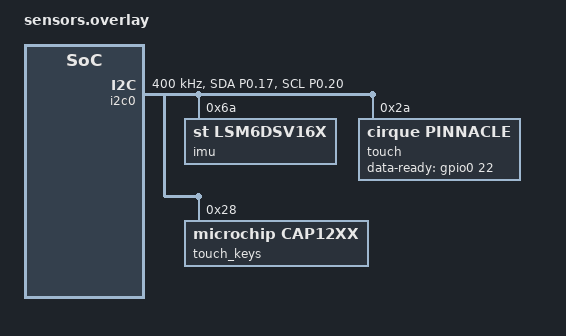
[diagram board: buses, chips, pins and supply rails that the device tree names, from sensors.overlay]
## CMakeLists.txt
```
# Copyright (c) 2026 the OpenSC2-Controller authors
# SPDX-License-Identifier: MIT
cmake_minimum_required(VERSION 3.20.0)

# The OpenSC2 library is a Zephyr module: the OpenSC2-Controller repository. Inside the repository
# it is found here. In a copy of this folder elsewhere, set ZEPHYR_EXTRA_MODULES to your
# OpenSC2-Controller folder (environment variable, or -DZEPHYR_EXTRA_MODULES=<folder>), or list the
# repository in your west manifest (docs/integration.md).
if(EXISTS ${CMAKE_CURRENT_LIST_DIR}/../zephyr/module.yml AND
   EXISTS ${CMAKE_CURRENT_LIST_DIR}/../include/opensc2/opensc2.h)
  list(APPEND ZEPHYR_EXTRA_MODULES ${CMAKE_CURRENT_LIST_DIR}/..)
endif()

# A build variant: a Kconfig fragment of this folder given as EXTRA_CONF_FILE brings the devicetree
# overlay of the same name with it, when there is one (sensors.conf and sensors.overlay). Under
# sysbuild the fragment's name is in the sysbuild cache, not yet a variable here.
set(variant_confs ${EXTRA_CONF_FILE})
if(NOT variant_confs AND DEFINED SYSBUILD_CACHE AND EXISTS "${SYSBUILD_CACHE}")
  file(STRINGS "${SYSBUILD_CACHE}" variant_line REGEX "^EXTRA_CONF_FILE:[A-Z]+=")
  string(REGEX REPLACE "^EXTRA_CONF_FILE:[A-Z]+=" "" variant_confs "${variant_line}")
endif()
# A fragment can build on others of this folder: a line "# OPENSC2_FRAGMENTS: a.conf b.conf" in it
# adds them, with their overlays, before it (all.conf). Zephyr merges this list with the one given.
set(variant_names)
set(variant_parts)
foreach(conf ${variant_confs})
  get_filename_component(variant ${conf} NAME_WE)
  if(EXISTS ${CMAKE_CURRENT_LIST_DIR}/${variant}.conf)
    file(STRINGS ${CMAKE_CURRENT_LIST_DIR}/${variant}.conf parts_line REGEX "^# OPENSC2_FRAGMENTS:")
    string(REGEX REPLACE "^# OPENSC2_FRAGMENTS:" "" parts "${parts_line}")
    separate_arguments(parts)
    foreach(part ${parts})
      list(APPEND variant_parts ${CMAKE_CURRENT_LIST_DIR}/${part})
      get_filename_component(part_name ${part} NAME_WE)
      list(APPEND variant_names ${part_name})
    endforeach()
  endif()
  list(APPEND variant_names ${variant})
endforeach()
if(variant_parts)
  set(EXTRA_CONF_FILE ${variant_parts} ${EXTRA_CONF_FILE})
endif()
foreach(variant ${variant_names})
  if(EXISTS ${CMAKE_CURRENT_LIST_DIR}/${variant}.overlay)
    list(APPEND EXTRA_DTC_OVERLAY_FILE ${CMAKE_CURRENT_LIST_DIR}/${variant}.overlay)
  endif()
endforeach()

find_package(Zephyr REQUIRED HINTS $ENV{ZEPHYR_BASE})
project(opensc2_app LANGUAGES C)

target_sources(app PRIVATE
	src/main.c
	src/inputs.c
	src/status.c
	src/rumble.c
	src/trackpad.c
	src/imu.c
	src/imu_fifo.c
	src/imu_board.c
	src/battery.c
	src/i2c_recover.c
)
```

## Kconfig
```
# Copyright (c) 2026 the OpenSC2-Controller authors
# SPDX-License-Identifier: MIT

menu "OpenSC2 blank canvas"

config APP_OBEY_BOOTLOADER_REQUEST
	bool "Reboot into the UF2 bootloader when Steam asks for a firmware update"
	help
	  Steam sends vendor command 0x90 to put a controller into its bootloader for an update.
	  This board's UF2 bootloader does not speak Steam's update protocol, so by default the
	  request is ignored and the firmware stays as it is. With this option the board opens its
	  UF2 drive instead; Steam's update still cannot run. To flash a new .uf2, short RST to GND
	  twice quickly, or use the shell command "uf2" (wireless mode).

config APP_ANALOG_SAMPLE
	bool "Read the sticks and triggers right before each state report, four conversions averaged"
	default y
	help
	  As the real controller: no analog thread; the axes are read in the library's sample
	  callback (in its radio or USB report thread), each converted four times and averaged, with
	  the sensors' supply (zephyr,user sensor-supply-gpios, optional) on only while they are
	  read, after sensor-supply-settle-us (200 by default). The readings are as fresh as the report
	  that carries them. Off: a thread of its own reads them every 4 ms. Untested on hardware.

config APP_ANALOG_RAW
	bool "Sticks and triggers through the library's stored calibration, as the real controller"
	depends on APP_ANALOG_SAMPLE && OPENSC2_CAL
	default y
	help
	  Every stick and trigger goes to the library as raw counts: the real controller's processing
	  with its stored calibration (cal/joy_l, cal/trg_l, ...), controller settings 46 and 62, and
	  the recordings of vendor commands 0xD8 and 0xC0 or of the shell's "opensc2 cal". As on the
	  real controller, a stick or trigger without a usable calibration reads 0 (calibrate it once:
	  "opensc2 cal sticks 1", "2", "3", and "opensc2 cal triggers ..."), unless
	  APP_ANALOG_SELF_CENTRE gives it this firmware's own centring until then. Untested on
	  hardware.

config APP_ANALOG_SELF_CENTRE
	bool "Without a stored calibration, centre each stick and trigger at boot"
	help
	  For boards without a stored calibration (potentiometer sticks, a board being built): a stick
	  or trigger that has none takes its resting value at boot as its centre or released end,
	  starts with a range of 40 % (80 % for a trigger) that grows as the input goes further, and has
	  a small centre dead zone; it gives setting 46's raw output itself. Off (the default), such an
	  input reads 0, as on the real controller. With APP_ANALOG_RAW off every input is handled
	  this way.

config APP_BATTERY
	bool "Measure the battery for report 0x43"
	select OPENSC2_BATTERY_GAUGE
	help
	  The library's fuel gauge (<opensc2/battery.h>) on this board's readings: the battery's
	  voltage through a divider plus cal/volt_offset, 40 readings with an average, the level with
	  OpenSC2's LiPo curves, kept over a warm reboot, and the real controller's charge states,
	  from a charger status pin (charger-status-gpios) or the library's charger model. Without a
	  "battery" io-channel in zephyr,user it reads the nRF52840's VDDH / 5, for a cell that feeds
	  VDDH; the system voltage is the chip's VDD, the input voltage an optional "input"
	  io-channel. Untested on a battery.

config APP_PWM
	bool
	default y if DT_HAS_NORDIC_NRF_PWM_ENABLED
	select PWM
	help
	  Set when the overlay enables a PWM instance (rumble motor, RGB LED).

config APP_I2C
	bool
	default y if DT_HAS_NORDIC_NRF_TWI_ENABLED || DT_HAS_NORDIC_NRF_TWIM_ENABLED
	select I2C
	help
	  Set when the overlay enables an I2C bus (touch module, IMU).

config APP_IMU
	bool
	default y if $(dt_alias_enabled,imu0)
	select SENSOR
	select OPENSC2_FUSION
	imply FPU
	help
	  Set when the overlay aliases a sensor as imu0.

config APP_IMU_STREAM
	bool "Stream an LSM6DSV16X's FIFO with its own fusion, as the real controller"
	depends on APP_IMU && LSM6DSV16X_STREAM
	help
	  Instead of reading any IMU every 4 ms: the FIFO of an ST LSM6DSV16X streamed with Zephyr's
	  sensor streaming API (CONFIG_SENSOR_ASYNC_API, CONFIG_I2C_RTIO and an interrupt pin), with
	  its own game rotation vector and gyro-bias estimate, from boot, at the real controller's
	  250 Hz (the chip's high-accuracy mode); the library's IMU (<opensc2/imu.h>) switches it with
	  setting 48 and subtracts the bias while setting 84 is on; the stored gyro bias is its
	  starting bias. app/imu-stream.conf builds it. Untested on hardware.

config APP_IMU_BIAS
	bool "Estimate the gyro's bias at rest and subtract it (settings 84 and 85)"
	depends on APP_IMU && !APP_IMU_STREAM
	help
	  For IMUs without a bias estimate of their own (the real controller takes its IMU's): a
	  rest-based estimate of OpenSC2's own, handed to the library's IMU as the sensor's bias, which
	  it subtracts while controller setting 84 is not 0 (the default), with setting 85 as its rest
	  threshold in report units (default 100, about 6 deg/s). It starts from the stored
	  cal/sensors/gyroscope/bias when there is one. Not with APP_IMU_STREAM, which takes the
	  LSM6DSV16X's own estimate. Untested on hardware.

config APP_PAD_PROCESSING
	bool "The real controller's trackpad processing on the touch devices"
	help
	  For a device with a touch strength (the Cirque Pinnacle): touch with the hysteresis of
	  controller settings 72 and 73 and the damping near lift-off, the strength scaled by
	  zephyr,user's trackpad-strength-scale (40 by default); the speed-adaptive position filter
	  while setting 65 is on; with a stored pressure calibration, the strength as the library's
	  raw pressure (its pressure and click). Untested on hardware.

config APP_I2C_RECOVER
	bool "Free each I2C bus at boot, before its parts' drivers start"
	depends on APP_I2C
	default y
	help
	  As the real controller does at every start of its I2C drivers: a reset in the middle of a
	  transfer can leave a part holding SDA low; clocking SCL frees it (Zephyr's
	  i2c_recover_bus()). On whenever the board has an I2C bus; turn it off only for a bus whose
	  driver cannot recover. Untested on hardware.

config APP_I2C_RECOVER_PRIORITY
	int "Init priority of the bus recovery (POST_KERNEL)"
	default 60
	depends on APP_I2C_RECOVER
	help
	  After the I2C drivers (CONFIG_I2C_INIT_PRIORITY, 50) and before the sensor and touch
	  drivers (90).

endmenu

source "Kconfig.zephyr"
```

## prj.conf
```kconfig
# Copyright (c) 2026 the OpenSC2-Controller authors
# SPDX-License-Identifier: MIT
#
# OpenSC2 blank canvas: a Steam Controller 2 for Valve's puck, wired or wireless (README.md).
# Pins are in boards/promicro_nrf52840_nrf52840_uf2.overlay; the SuperMini's own Kconfig lines (its
# clock) are in boards/promicro_nrf52840_nrf52840_uf2.conf. Every option: docs/api.md.

# ---- the library ------------------------------------------------------------------------------
CONFIG_OPENSC2=y
# The puck sends packets of up to 128 bytes; the real controller keeps two replies queued.
CONFIG_ESB_MAX_PAYLOAD_LENGTH=128
CONFIG_ESB_TX_FIFO_SIZE=2
CONFIG_ESB_RX_FIFO_SIZE=8

# Identity reported to Steam. The defaults are development values: "OSC"/"OSB" serials made from
# the chip's ID (CONFIG_OPENSC2_SERIAL_FROM_CHIP), not a real controller's. Uncomment to choose
# your own (13 characters, 0-9 and A-Z; keep the OSC prefix, the hardware test suite only talks
# to boards whose serial starts with OSC), or set them on the board:
# `opensc2 id set unit OSC2MYBOARD01`.
#CONFIG_OPENSC2_SERIAL_FROM_CHIP=n
#CONFIG_OPENSC2_UNIT_SERIAL="OSC2DEV000001"
#CONFIG_OPENSC2_BOARD_SERIAL="OSC2PCB000001"
# The firmware revision Steam reads (1 to 12 characters): this release.
CONFIG_OPENSC2_GIT_REVISION="osc2-0.2.0"

# Hardware test hooks for tools/hwtest, on so that the suite tests this very image. Inert until
# the suite arms them (a keyed vendor command 0x7E over USB or through the puck, or
# "opensc2 test" on the console; RAM only, gone at every reboot but for a boot-time injection
# stored for the next boot, and the lease ends it when the PC goes quiet): unarmed the board
# answers exactly as without them. The key is published with
# the code, so it stops accidents, not a program that wants to send controller input (a local
# program can create desktop input anyway); mouse and keyboard reports never leave the board
# while armed. About 3 KB of RAM. For a board you give to someone else, set it to n.
CONFIG_OPENSC2_TEST_HOOKS=y

# ---- wired mode: the board as a USB Steam Controller 2 (28DE:1302) ------------------------------
# On by default (the overlay chooses its HID node). At a boot with USB power the board comes up
# wired, as the real controller does; hold the pairing button while plugging in for wireless.
# The library runs the USB device itself, so the board's own serial port is off; in wireless
# mode the library shows the same console (CONFIG_OPENSC2_USB_CONSOLE).
CONFIG_CDC_ACM_SERIAL_INITIALIZE_AT_BOOT=n
# Eight input reports may wait for the host at once; nothing ever blocks on it.
CONFIG_USBD_HID_IN_BUF_COUNT=8
# Vendor commands that write flash (Steam's bond) run in the USB stack's thread.
CONFIG_USBD_THREAD_STACK_SIZE=2048
CONFIG_SYSTEM_WORKQUEUE_STACK_SIZE=2048
# The USB identity form (October 2026 by default, the current controller firmware's, which Steam
# paired with the v0.2.0 release image; July's was the 2026-10-19 snapshot's default, which Steam
# paired too):
#CONFIG_OPENSC2_USB_PROFILE_JULY=y
# Never wired, until changed with `opensc2 mode auto`:
#CONFIG_OPENSC2_DEFAULT_POLICY_WIRELESS=y
# No USB console in wireless mode, like the real controller:
#CONFIG_OPENSC2_USB_CONSOLE=n
# Wired with no PC (a USB charger), this build waits, as the real controller does, until a PC sets
# it up or STEAM is pressed. test-charger.conf is a separate TEST build for a board without
# buttons (wireless after 5 s without a host); it is not part of this default build.

# ---- inputs and outputs -----------------------------------------------------------------------
CONFIG_GPIO=y
CONFIG_INPUT=y
CONFIG_ADC=y
# PWM (rumble motor, RGB LED) is switched on by the overlay: enable a PWM instance there.

# ---- bonds and the stored identity: Zephyr settings on NVS, in the board's storage partition ----
CONFIG_FLASH=y
CONFIG_FLASH_MAP=y
CONFIG_NVS=y
CONFIG_SETTINGS=y
CONFIG_SETTINGS_NVS=y

# ---- system -------------------------------------------------------------------------------------
CONFIG_REBOOT=y
CONFIG_MAIN_STACK_SIZE=2048

# Log and shell ("opensc2 status", "opensc2 usb log", "uf2", ...) on the USB serial port in
# wireless mode. While wired the log goes into the USB session log instead.
CONFIG_LOG=y
CONFIG_SHELL=y
CONFIG_LOG_BACKEND_UART=n
# The log thread also writes the log into the session log while wired: more stack than 768 bytes.
CONFIG_LOG_PROCESS_THREAD_STACK_SIZE=1536
CONFIG_SHELL_PROMPT_UART="opensc2:~$ "

# ---- Bluetooth LE, the haptics synthesiser and pad clicks by pressure: in the default build -----
# Like the real controller, the board talks to the PC through Bluetooth OR the puck, one at a time
# (the stored transport; chords and `opensc2 transport` switch). The settings below are
# ble.conf's (its notes explain each one) and haptics.conf's.
CONFIG_OPENSC2_BLE=y
CONFIG_BT=y
CONFIG_BT_PERIPHERAL=y
CONFIG_BT_MAX_CONN=1
CONFIG_BT_CTLR_TX_PWR_PLUS_6=y
CONFIG_BT_SMP=y
CONFIG_BT_SMP_SC_PAIR_ONLY=y
CONFIG_BT_BONDABLE=y
CONFIG_BT_SETTINGS=y
CONFIG_BT_ID_MAX=5
CONFIG_BT_MAX_PAIRED=5
CONFIG_BT_FILTER_ACCEPT_LIST=y
CONFIG_BT_ID_UNPAIR_MATCHING_BONDS=y
CONFIG_BT_ID_ALLOW_UNAUTH_OVERWRITE=y
CONFIG_BT_DEVICE_NAME_DYNAMIC=y
CONFIG_BT_DEVICE_NAME_MAX=31
CONFIG_BT_DEVICE_NAME="Steam Ctrl (BT)"
CONFIG_BT_DEVICE_APPEARANCE=964
CONFIG_BT_BUF_ACL_RX_SIZE=71
CONFIG_BT_BUF_ACL_TX_SIZE=71
CONFIG_BT_L2CAP_TX_MTU=67
CONFIG_BT_ATT_PREPARE_COUNT=4
CONFIG_BT_AUTO_DATA_LEN_UPDATE=n
CONFIG_BT_BUF_ACL_TX_COUNT=8
CONFIG_BT_L2CAP_TX_BUF_COUNT=8
CONFIG_BT_ATT_TX_COUNT=10
CONFIG_BT_PERIPHERAL_PREF_MIN_INT=6
CONFIG_BT_PERIPHERAL_PREF_MAX_INT=6
CONFIG_BT_PERIPHERAL_PREF_LATENCY=0
CONFIG_BT_PERIPHERAL_PREF_TIMEOUT=42
CONFIG_BT_GAP_AUTO_UPDATE_CONN_PARAMS=y
CONFIG_BT_AUTO_PHY_PERIPHERAL_2M=y
CONFIG_BT_USER_PHY_UPDATE=y
CONFIG_BT_REMOTE_INFO=n
CONFIG_BT_BAS=y
CONFIG_BT_RX_STACK_SIZE=3072
CONFIG_OPENSC2_HAPTICS_SYNTH=y
# The pads click from their pressure (settings 52 and 53), as the real ones do.
CONFIG_OPENSC2_PAD_CLICK_AUTO=y
```

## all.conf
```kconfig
# Copyright (c) 2026 the OpenSC2-Controller authors
# SPDX-License-Identifier: MIT
#
# EVERYTHING THAT NEEDS NO PARTS: a test build of the blank canvas with Bluetooth LE, the haptics
# synthesiser, the dock link and the hardware watchdog together, on top of prj.conf, which already
# has the first three: what this build adds is the watchdog. Built; NOT YET TESTED ON HARDWARE, and
# neither the default firmware nor part of any release. Build it on purpose, in a build folder of
# its own:
#
#   powershell -NoProfile -ExecutionPolicy Bypass -File build.ps1 -Project app\all.conf -OutDir C:\b\osc2-all -Pristine
#   west build -p always -d build-all -b promicro_nrf52840/nrf52840/uf2 app -- -DEXTRA_CONF_FILE=all.conf
#
# It builds on three fragments of this folder, which app/CMakeLists.txt adds before this one (the
# OPENSC2_FRAGMENTS line below names them); read their notes first: ble.conf (the board still boots
# on the puck until Bluetooth is chosen), haptics.conf, and watchdog.conf (the watchdog cannot be
# stopped, and has not been tried with the UF2 bootloader: how to flash the board again is there).
# OPENSC2_FRAGMENTS: ble.conf haptics.conf watchdog.conf
#
# Left out because they need parts: sensors.conf, imu-stream.conf and expander.conf (sensors and a
# port expander on pins of their own), battery.conf (a battery: without one a shutdown that powers
# off could not be woken), and dock.conf (the dock's UART and pilot sense take four button pins and
# need a front end). test-charger.conf is a test aid of its own. All four features fit together:
# about 397 KB of flash and 94 KB of RAM.

# The dock link: the protocol without pins, which the test hooks feed (on with them by default;
# named here so that it stays on).
CONFIG_OPENSC2_DOCK_LINK=y
```

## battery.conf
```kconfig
# Copyright (c) 2026 the OpenSC2-Controller authors
# SPDX-License-Identifier: MIT
#
# A BATTERY BUILD of the blank canvas, on top of prj.conf: for a SuperMini with a LiPo on its
# battery pads. NOT tested on hardware yet. Build it on purpose, in a build folder of its own
# (README.md, "Build options"):
#
#   powershell -NoProfile -ExecutionPolicy Bypass -File build.ps1 -Project app\battery.conf -OutDir C:\b\osc2-bat -Pristine
#   west build -p always -d build-battery -b promicro_nrf52840/nrf52840/uf2 app -- -DEXTRA_CONF_FILE=battery.conf
#
# What changes (docs/api.md, "Power and the system state machine"): without USB power the board runs
# on its battery, as the real controller does. STEAM held 7 s, Steam's "turn off", the idle timeout
# (controller setting 50, 15 minutes by default), a puck that is gone (60 s of listening, 10 s with
# an empty bond slot), 0 % battery, and the cable pulled while wired turn the board off (System
# OFF). STEAM wakes it (the pin of the gpio-keys key with OPENSC2_KEY_STEAM; without one, any key),
# and so does plugging in USB. On USB power nothing changes.
#
# This board measures no battery voltage: the level stays 100 % unless an application sets one, so
# low battery never turns it off. A charger with a status output can give the charge state
# (charger-status-gpios in the overlay). Without a STEAM button wired, only a USB cable or a reset
# brings a board back that has turned itself off.
CONFIG_OPENSC2_BATTERY=y
```

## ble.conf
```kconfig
# Copyright (c) 2026 the OpenSC2-Controller authors
# SPDX-License-Identifier: MIT
#
# THE BLUETOOTH SETTINGS: prj.conf has them all (Bluetooth LE is in the default build, as on the
# real controller); this fragment keeps the notes on each and still builds on its own, the same
# firmware as prj.conf alone. Bluetooth LE as a wireless transport next to the puck: the board as a
# HID-over-GATT Steam Controller 2 (PnP ID 28DE:1303). Tested on hardware with Windows on the
# v0.2.0 release image (Windows pairs it, it reconnects after a reboot, Steam drives it, and the
# hardware test suite's --bluetooth path passes; docs/testing.md, "Results so far"); phones, SDL
# and Valve's vendor GATT service have not been tested. Older build commands still work, on top of
# prj.conf, in a build folder of its own (app/README.md, "Bluetooth LE"):
#
#   powershell -NoProfile -ExecutionPolicy Bypass -File build.ps1 -Project app\ble.conf -OutDir C:\b\osc2-ble -Pristine
#   west build -p always -d build-ble -b promicro_nrf52840/nrf52840/uf2 app -- -DEXTRA_CONF_FILE=ble.conf
#
# The board still boots wired on USB power and wireless on the stored transport, the puck by
# default. On its console: "opensc2 transport ble" switches to Bluetooth (and it is stored once a
# host has connected and encrypted the link), "opensc2 ble status" shows the link, "opensc2 ble
# pair" opens the slot for a new host. "opensc2 transport puck" goes back. Every option:
# docs/api.md, Bluetooth LE.

# ---- the library ----------------------------------------------------------------------------
CONFIG_OPENSC2_BLE=y

# ---- the stack: Nordic's SoftDevice Controller (peripheral only) and Zephyr's host -------------
CONFIG_BT=y
CONFIG_BT_PERIPHERAL=y
CONFIG_BT_MAX_CONN=1
# +6 dBm, as the real controller (and the puck's link) use.
CONFIG_BT_CTLR_TX_PWR_PLUS_6=y

# Just Works pairing with LE Secure Connections only (no legacy pairing), bonding, keys of 16
# bytes. No input or output: no passkey, no confirmation.
CONFIG_BT_SMP=y
CONFIG_BT_SMP_SC_PAIR_ONLY=y
CONFIG_BT_BONDABLE=y
# Five identities (0 is never used to advertise; 1 and 2 are slot 1, 3 and 4 slot 2) and room for
# five bonds; bonds and identities stored with the settings.
CONFIG_BT_SETTINGS=y
CONFIG_BT_ID_MAX=5
CONFIG_BT_MAX_PAIRED=5
CONFIG_BT_FILTER_ACCEPT_LIST=y
# A host that bonds again on another identity loses its older bond; an unauthenticated pairing may
# replace keys held on another identity, never those of the identity in use (a host that pairs
# again on the identity it is bonded to is refused: pairing mode, `opensc2 ble pair`, gives it a
# fresh identity).
CONFIG_BT_ID_UNPAIR_MATCHING_BONDS=y
CONFIG_BT_ID_ALLOW_UNAUTH_OVERWRITE=y

# The name ("Steam Ctrl (BT) " and the unit serial: 29 characters), set at every boot; the
# appearance: gamepad (0x03C4).
CONFIG_BT_DEVICE_NAME_DYNAMIC=y
CONFIG_BT_DEVICE_NAME_MAX=31
CONFIG_BT_DEVICE_NAME="Steam Ctrl (BT)"
CONFIG_BT_DEVICE_APPEARANCE=964

# Buffers for 67-byte ATT packets: L2CAP packets of up to 71 bytes, an ATT MTU of 67 offered, and
# four prepare-write buffers so a host at the default MTU can still write the 64-byte feature
# report. The controller never starts a data-length update itself (a host may).
CONFIG_BT_BUF_ACL_RX_SIZE=71
CONFIG_BT_BUF_ACL_TX_SIZE=71
CONFIG_BT_L2CAP_TX_MTU=67
CONFIG_BT_ATT_PREPARE_COUNT=4
CONFIG_BT_AUTO_DATA_LEN_UPDATE=n
CONFIG_BT_BUF_ACL_TX_COUNT=8
CONFIG_BT_L2CAP_TX_BUF_COUNT=8
CONFIG_BT_ATT_TX_COUNT=10

# Connection parameters: 7.5 ms, latency 0, 420 ms supervision timeout, asked for 5 s after the
# connection starts; the 2M PHY asked for at once, and the PHYs logged at connection and at every
# change. The host's version and features are not read.
CONFIG_BT_PERIPHERAL_PREF_MIN_INT=6
CONFIG_BT_PERIPHERAL_PREF_MAX_INT=6
CONFIG_BT_PERIPHERAL_PREF_LATENCY=0
CONFIG_BT_PERIPHERAL_PREF_TIMEOUT=42
CONFIG_BT_GAP_AUTO_UPDATE_CONN_PARAMS=y
CONFIG_BT_AUTO_PHY_PERIPHERAL_2M=y
CONFIG_BT_USER_PHY_UPDATE=y
CONFIG_BT_REMOTE_INFO=n

# The Battery Service (Zephyr's); the Device Information Service and the HID service are the
# library's own.
CONFIG_BT_BAS=y

# Vendor commands run in the host's receive thread when a host writes feature report 1, and some
# write flash (0xEF, the bond).
CONFIG_BT_RX_STACK_SIZE=3072
```

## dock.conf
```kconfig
# Copyright (c) 2026 the OpenSC2-Controller authors
# SPDX-License-Identifier: MIT
#
# THE DOCK BUILD: BUILT, NEVER RUN ON HARDWARE, and not the default firmware. The SuperMini as a
# controller that can rest on Valve's puck: the dock's UART and pilot sense (CONFIG_OPENSC2_DOCK)
# on four pins that are buttons in the default build (dock.overlay, which app/CMakeLists.txt adds
# with this fragment, says which). Build it on purpose, in a build folder of its own:
#
#   powershell -NoProfile -ExecutionPolicy Bypass -File build.ps1 -Project app\dock.conf -OutDir C:\b\osc2-dock -Pristine
#
# NOTHING MAY BE CONNECTED TO VALVE'S PUCK'S PADS without the owner's step-by-step go-ahead: the
# pads' voltages and loads have not been measured, and the puck's + pad carries about 5 V once the
# puck switches it on (docs/testing.md, The dock). Try the build against a USB-UART adapter acting
# as the puck first (tools/fake_puck.py).
#
# The dock link itself (the frames, the requests, the test hooks' dock ops) is in the default
# build too, without pins.
CONFIG_OPENSC2_DOCK=y

# The dock's UART (UARTE1) on the async API; the debug console stays on USB.
CONFIG_SERIAL=y
CONFIG_UART_ASYNC_API=y
CONFIG_UART_1_INTERRUPT_DRIVEN=n
CONFIG_UART_1_ASYNC=y
```

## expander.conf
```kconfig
# Copyright (c) 2026 the OpenSC2-Controller authors
# SPDX-License-Identifier: MIT
#
# A build of the blank canvas with every button of the real controller (app/README.md):
#   build.ps1 -Project app\expander.conf
# with expander.overlay, which app/CMakeLists.txt adds with it: an I2C port expander (an NXP
# PCA9555) carries the four grip buttons and the two D-pad buttons whose pins the bus takes, read
# when its INT output says an input changed (on the left trigger button's pin, P0.24), as the real
# controller reads its expander. Untested on hardware.

# The bus is freed at boot, as the real controller does, before the expander's driver starts
# (the recovery runs at priority 60, the expander after it).
CONFIG_APP_I2C_RECOVER=y
CONFIG_GPIO_PCA95XX_INIT_PRIORITY=70
# The expander's INT output: read only when an input changed.
CONFIG_GPIO_PCA95XX_INTERRUPT=y
```

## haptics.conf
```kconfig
# Copyright (c) 2026 the OpenSC2-Controller authors
# SPDX-License-Identifier: MIT
#
# THE HAPTICS BUILD: the blank canvas with the haptics synthesiser on (CONFIG_OPENSC2_HAPTICS_SYNTH),
# a Kconfig fragment on top of prj.conf. The synthesiser is on by default now (in the library and
# in prj.conf), so this fragment only keeps older build commands working: it builds the same
# firmware as prj.conf alone. On the v0.2.0 release image the hardware test suite checks, with
# nothing wired, how the synthesiser handles the haptic reports (below); its sound has never been
# heard, as no actuator has been on a test board. From the repository folder:
#
#   powershell -NoProfile -ExecutionPolicy Bypass -File build.ps1 -Project app\haptics.conf -OutDir C:\b\osc2-hap -Pristine
#   west build -p always -d build-haptics -b promicro_nrf52840/nrf52840/uf2 app -- -DEXTRA_CONF_FILE=haptics.conf
#
# Always in a build folder of its own (a folder's CMake cache keeps the fragment).
#
# What it adds: the library renders every haptic output report (rumble, pulses, clicks, tones,
# sweeps, scripts, PCM streams) into sample blocks for the pads (4 kHz) and the grips (8 kHz),
# plays OpenSC2's own built-in sounds and sends the streams' flow control (input report 0x44).
# With nothing wired the blocks go nowhere, paced by a timer, and the hardware test suite checks
# them through the test hooks (run on the release image) (tools/hwtest, group "haptics": CRCs of rendered blocks, generator
# starts and stops, the stream flags). With a vibration motor on the overlay's "rumble" PWM
# channel (samples/rumble's wiring), the motor follows the rendered blocks' loudness instead of the
# decoded reports. Real actuator outputs (an I2S amplifier, the pads' PWM DAC, a DRV2605):
# samples/haptics.
CONFIG_OPENSC2_HAPTICS_SYNTH=y
```

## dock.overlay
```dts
/*
 * Copyright (c) 2026 the OpenSC2-Controller authors
 * SPDX-License-Identifier: MIT
 *
 * The dock build's pins (app/dock.conf; app/CMakeLists.txt adds this overlay with that fragment),
 * on top of boards/promicro_nrf52840_nrf52840_uf2.overlay. BUILT, NEVER RUN ON HARDWARE.
 *
 * The SuperMini has no free pins, so four change jobs:
 *
 *   P0.31 (AIN7)  the pilot sense, an analog input with no divider   (was the pairing button)
 *   P1.06         the pairing button                                  (was QAM)
 *   P1.01         the dock UART's TX, open drain: it pulls the line low for a 0 bit and leaves it
 *                 alone otherwise, so it never holds the pilot at 3.3 V   (was RT, digital)
 *   P1.02         the dock UART's RX, no pull                          (was R3)
 *
 * The dock's + pad is not wired: as on the real controller VBUS stands for it, so USB power that
 * appears while the pilot reads inside its window counts as the dock's power. Tie P0.31 to ground
 * through a resistor when nothing is attached, or a floating pin can make a USB boot a docked one.
 *
 * How these meet the puck's P pad (the pilot and the UART share it on the puck's side, inferred)
 * is not known: the pad's idle voltage and load have not been measured. A front end with series
 * resistors and clamps comes first, tried against a USB-UART adapter acting as the puck
 * (tools/fake_puck.py). NOTHING MAY BE CONNECTED TO VALVE'S PUCK'S PADS without the owner's
 * step-by-step go-ahead (docs/testing.md, The dock).
 */

/ {
	aliases {
		opensc2-dock = &opensc2_dock;
	};

	/* The dock link's UART and pilot channel (dts/bindings/opensc2,dock.yaml). */
	opensc2_dock: opensc2-dock {
		compatible = "opensc2,dock";
		uart = <&uart1>;
		io-channels = <&adc 2>;
	};
};

/* The pairing button moves from P0.31 to QAM's pin; QAM, RT (digital) and R3 give theirs up. */
&opensc2_pair {
	gpios = <&gpio1 6 (GPIO_PULL_UP | GPIO_ACTIVE_LOW)>;
};

&opensc2_buttons {
	/delete-node/ qam;
	/delete-node/ trigger_r;
	/delete-node/ stick_r;
};

&pinctrl {
	opensc2_dock_uart_default: opensc2_dock_uart_default {
		group1 {
			psels = <NRF_PSEL(UART_TX, 1, 1)>;
			nordic,drive-mode = <NRF_DRIVE_S0D1>;   /* open drain */
		};
		group2 {
			psels = <NRF_PSEL(UART_RX, 1, 2)>;
			bias-disable;
		};
	};

	opensc2_dock_uart_sleep: opensc2_dock_uart_sleep {
		group1 {
			psels = <NRF_PSEL(UART_TX, 1, 1)>,
				<NRF_PSEL(UART_RX, 1, 2)>;
			low-power-enable;
		};
	};
};

/* 115200 baud, 8N1, no flow control, as the puck's end. */
&uart1 {
	status = "okay";
	current-speed = <115200>;
	pinctrl-0 = <&opensc2_dock_uart_default>;
	pinctrl-1 = <&opensc2_dock_uart_sleep>;
	pinctrl-names = "default", "sleep";
};

/* The pilot: gain 1/6 of the internal 0.6 V reference, 12 bits (3600 mV full scale), no
 * divider; present inside 2000 to 3300 mV at the pin. */
&adc {
	channel@2 {
		reg = <2>;
		zephyr,gain = "ADC_GAIN_1_6";
		zephyr,reference = "ADC_REF_INTERNAL";
		zephyr,acquisition-time = <ADC_ACQ_TIME(ADC_ACQ_TIME_MICROSECONDS, 10)>;
		zephyr,input-positive = <NRF_SAADC_AIN7>;   /* P0.31 */
		zephyr,resolution = <12>;
	};
};
```

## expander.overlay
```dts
/*
 * Copyright (c) 2026 the OpenSC2-Controller authors
 * SPDX-License-Identifier: MIT
 *
 * The devicetree half of the build expander.conf (app/CMakeLists.txt adds it with that fragment):
 * every button of the real controller on a SuperMini. The real controller reads most of its
 * buttons through an I2C input expander, debounced 16 ms; here an NXP PCA9555 (16 inputs with
 * their own pull-ups) on I2C, SDA P0.17 and SCL P0.20, the pins of the left and right D-pad
 * buttons (as in sensors.overlay). Those two D-pad buttons and the four grip buttons go to the
 * expander's port 0, each between its pin and GND:
 *
 *   pin 0  D-pad left     pin 2  L4 (left upper grip)    pin 4  R4 (right upper grip)
 *   pin 1  D-pad right    pin 3  L5 (left lower grip)    pin 5  R5 (right lower grip)
 *
 * Pins 6 to 15 are free for more. Like the real controller's expander, the PCA9555 tells the
 * nRF52840 on an interrupt line: INT goes to P0.24, the left trigger button's pin (that button
 * moves off the board, as in imu-stream.overlay), so the bus stays quiet while no button moves.
 * The real controller's expander holds its line while any button is down and its buttons are then
 * read until all are up; the PCA9555's line marks a change instead, so it is read at each change. gpio-keys then debounces 16 ms, as it does
 * the buttons on the nRF52840's own pins here. A module without its INT wired: delete the
 * interrupt-gpios line and put polling-mode back into opensc2_buttons_polled (read every 16 ms).
 * Untested on hardware: check the address (0x20 with A0, A1 and A2 low) and the pins against your
 * module.
 */
#include <zephyr/dt-bindings/i2c/i2c.h>
#include <dt-bindings/opensc2/inputs.h>

/ {
	/* The label is the one app/src/inputs.c looks for: a second gpio-keys, polled or (here) on
	 * the expander's interrupt. */
	opensc2_buttons_polled: opensc2_buttons_polled {
		compatible = "gpio-keys";
		debounce-interval-ms = <16>;
		/* the expander's pins cannot be disconnected on suspend */
		no-disconnect;

		dpad_left  { gpios = <&expander 0 GPIO_ACTIVE_LOW>; zephyr,code = <OPENSC2_KEY_DPAD_LEFT>; };
		dpad_right { gpios = <&expander 1 GPIO_ACTIVE_LOW>; zephyr,code = <OPENSC2_KEY_DPAD_RIGHT>; };
		grip_l4    { gpios = <&expander 2 GPIO_ACTIVE_LOW>; zephyr,code = <OPENSC2_KEY_L4>; };
		grip_l5    { gpios = <&expander 3 GPIO_ACTIVE_LOW>; zephyr,code = <OPENSC2_KEY_L5>; };
		grip_r4    { gpios = <&expander 4 GPIO_ACTIVE_LOW>; zephyr,code = <OPENSC2_KEY_R4>; };
		grip_r5    { gpios = <&expander 5 GPIO_ACTIVE_LOW>; zephyr,code = <OPENSC2_KEY_R5>; };
	};
};

&opensc2_buttons {
	debounce-interval-ms = <16>;
	/delete-node/ dpad_left;
	/delete-node/ dpad_right;
	/delete-node/ trigger_l;   /* its pin carries the expander's INT */
};

&pinctrl {
	i2c0_expander_default: i2c0_expander_default {
		group1 {
			psels = <NRF_PSEL(TWIM_SDA, 0, 17)>, <NRF_PSEL(TWIM_SCL, 0, 20)>;
		};
	};
	i2c0_expander_sleep: i2c0_expander_sleep {
		group1 {
			psels = <NRF_PSEL(TWIM_SDA, 0, 17)>, <NRF_PSEL(TWIM_SCL, 0, 20)>;
			low-power-enable;
		};
	};
};

&i2c0 {
	status = "okay";
	clock-frequency = <I2C_BITRATE_FAST>;
	pinctrl-0 = <&i2c0_expander_default>;
	pinctrl-1 = <&i2c0_expander_sleep>;
	pinctrl-names = "default", "sleep";

	expander: gpio@20 {
		compatible = "nxp,pca95xx";
		reg = <0x20>;
		gpio-controller;
		#gpio-cells = <2>;
		ngpios = <16>;
		/* open drain, active low: the nRF52840's pull-up */
		interrupt-gpios = <&gpio0 24 (GPIO_PULL_UP | GPIO_ACTIVE_LOW)>;
	};
};
```

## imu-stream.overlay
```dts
/*
 * Copyright (c) 2026 the OpenSC2-Controller authors
 * SPDX-License-Identifier: MIT
 *
 * The devicetree half of the build imu-stream.conf (app/CMakeLists.txt adds it with that
 * fragment): the real controller's IMU, an ST LSM6DSV16X, on I2C instead of the two D-pad buttons
 * whose pins it takes (left P0.17 is SDA, right P0.20 is SCL), its INT1 on the left trigger
 * button's pin (P0.24), set up as the real controller sets its own: +-2 g and +-2000 deg/s at
 * 250 Hz in the chip's high-accuracy mode (LSM6DSVXXX_DT_ODR_HA01_AT_250Hz), a FIFO watermark of 4,
 * the 240 Hz batch rates and the fusion block at 240 Hz (in the high-accuracy mode the chip runs
 * them at the 250 Hz grid) with its game rotation vector and gyro-bias estimate in the FIFO, and
 * the real controller's mounting matrix. Not done here: the real controller's fusion alpha-blend
 * (written into the chip's embedded-function registers on its early boards) and its free-fall
 * time window (the stock driver reports no free fall in the stream; the library's software
 * detector stands in). Untested on hardware: check the pins and the address (0x6A, or 0x6B with
 * its SA0 pin high) against your board.
 */
#include <zephyr/dt-bindings/i2c/i2c.h>
#include <zephyr/dt-bindings/sensor/lsm6dsv16x.h>

/ {
	aliases {
		imu0 = &imu;
	};

	zephyr,user {
		/* The real controller's mounting: x' = y, y' = -x, z' = z (row major). */
		imu-mounting-matrix = <0 1 0 (-1) 0 0 0 0 1>;
	};
};

&opensc2_buttons {
	/delete-node/ dpad_left;
	/delete-node/ dpad_right;
	/delete-node/ trigger_l;
};

&pinctrl {
	i2c0_imu_default: i2c0_imu_default {
		group1 {
			psels = <NRF_PSEL(TWIM_SDA, 0, 17)>, <NRF_PSEL(TWIM_SCL, 0, 20)>;
		};
	};
	i2c0_imu_sleep: i2c0_imu_sleep {
		group1 {
			psels = <NRF_PSEL(TWIM_SDA, 0, 17)>, <NRF_PSEL(TWIM_SCL, 0, 20)>;
			low-power-enable;
		};
	};
};

&i2c0 {
	status = "okay";
	clock-frequency = <I2C_BITRATE_FAST>;
	pinctrl-0 = <&i2c0_imu_default>;
	pinctrl-1 = <&i2c0_imu_sleep>;
	pinctrl-names = "default", "sleep";

	imu: lsm6dsv16x@6a {
		compatible = "st,lsm6dsv16x";
		reg = <0x6a>;
		int1-gpios = <&gpio0 24 GPIO_ACTIVE_HIGH>;
		drdy-pin = <1>;
		accel-range = <LSM6DSV16X_DT_FS_2G>;
		gyro-range = <LSM6DSV16X_DT_FS_2000DPS>;
		accel-odr = <LSM6DSVXXX_DT_ODR_HA01_AT_250Hz>;
		gyro-odr = <LSM6DSVXXX_DT_ODR_HA01_AT_250Hz>;
		fifo-watermark = <4>;
		accel-fifo-batch-rate = <LSM6DSVXXX_DT_XL_BATCHED_AT_240Hz>;
		gyro-fifo-batch-rate = <LSM6DSVXXX_DT_GY_BATCHED_AT_240Hz>;
		sflp-odr = <LSM6DSVXXX_DT_SFLP_ODR_AT_240Hz>;
		sflp-fifo-enable = <LSM6DSVXXX_DT_SFLP_FIFO_GAME_ROTATION_GBIAS>;
	};
};
```

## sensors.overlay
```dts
/*
 * Copyright (c) 2026 the OpenSC2-Controller authors
 * SPDX-License-Identifier: MIT
 *
 * The devicetree half of the build sensors.conf (app/CMakeLists.txt adds it with that fragment):
 * the real controller's IMU, an ST LSM6DSV16X, on I2C instead of the two D-pad buttons whose pins
 * it takes (left P0.17 is SDA, right P0.20 is SCL, the pins samples/imu uses), with the real
 * controller's ranges and rates and its mounting matrix; a Cirque Pinnacle module on the same bus
 * as the right trackpad, its data-ready line on the left bumper's pin (P0.22), as samples/touchpad
 * has it; and a Microchip CAP1206 capacitive sensor, polled, whose first four inputs (CS1 to CS4)
 * give the left and right stick-touch and the left and right grip bits. Untested on hardware:
 * check the pins and the addresses (0x6A, or 0x6B with the IMU's SA0 pin high; 0x2A; 0x28)
 * against your board.
 */
#include <zephyr/dt-bindings/i2c/i2c.h>
#include <zephyr/dt-bindings/sensor/lsm6dsv16x.h>
#include <dt-bindings/opensc2/inputs.h>

/ {
	aliases {
		imu0 = &imu;
	};

	chosen {
		opensc2,right-trackpad = &touch;
		opensc2,touch-keys = &touch_keys;
	};

	zephyr,user {
		right-trackpad-size = <1024 1024>;
		/* The real controller's mounting: x' = y, y' = -x, z' = z (row major). Use the one
		 * that turns your module's axes into the controller's: X right, Y away from the
		 * player, Z up when it lies flat. */
		imu-mounting-matrix = <0 1 0 (-1) 0 0 0 0 1>;
	};
};

&opensc2_buttons {
	/delete-node/ dpad_left;
	/delete-node/ dpad_right;
	/delete-node/ bumper_l;
};

&pinctrl {
	i2c0_sensors_default: i2c0_sensors_default {
		group1 {
			psels = <NRF_PSEL(TWIM_SDA, 0, 17)>, <NRF_PSEL(TWIM_SCL, 0, 20)>;
		};
	};
	i2c0_sensors_sleep: i2c0_sensors_sleep {
		group1 {
			psels = <NRF_PSEL(TWIM_SDA, 0, 17)>, <NRF_PSEL(TWIM_SCL, 0, 20)>;
			low-power-enable;
		};
	};
};

&i2c0 {
	status = "okay";
	clock-frequency = <I2C_BITRATE_FAST>;
	pinctrl-0 = <&i2c0_sensors_default>;
	pinctrl-1 = <&i2c0_sensors_sleep>;
	pinctrl-names = "default", "sleep";

	imu: lsm6dsv16x@6a {
		compatible = "st,lsm6dsv16x";
		reg = <0x6a>;
		/* the real controller's +-2 g and +-2000 deg/s, at 240 Hz: the real controller runs at
		 * 250 Hz, a rate of the chip's high-accuracy mode (LSM6DSVXXX_DT_ODR_HA01_AT_250Hz)
		 */
		accel-range = <LSM6DSV16X_DT_FS_2G>;
		gyro-range = <LSM6DSV16X_DT_FS_2000DPS>;
		accel-odr = <LSM6DSVXXX_DT_ODR_AT_240Hz>;
		gyro-odr = <LSM6DSVXXX_DT_ODR_AT_240Hz>;
	};

	touch: trackpad@2a {
		compatible = "cirque,pinnacle";
		reg = <0x2a>;
		data-ready-gpios = <&gpio0 22 GPIO_ACTIVE_HIGH>;
		data-mode = "absolute";
		idle-packets-count = <1>;
		clipping-enable;
		scaling-enable;
		scaling-x-resolution = <1024>;
		scaling-y-resolution = <1024>;
	};

	/* Stick touch and grips: the sensor's own thresholds decide (settings 30, 31, 34 and 35
	 * apply only to raw words given with opensc2_set_touch_raw()). */
	touch_keys: cap1206@28 {
		compatible = "microchip,cap12xx";
		reg = <0x28>;
		poll-interval-ms = <10>;
		input-codes = <OPENSC2_KEY_LEFT_STICK_TOUCH OPENSC2_KEY_RIGHT_STICK_TOUCH
			       OPENSC2_KEY_LEFT_GRIP_TOUCH OPENSC2_KEY_RIGHT_GRIP_TOUCH>;
		signal-guard = <0 0 0 0>;
		calib-sensitivity = <1 1 1 1>;
	};
};
```

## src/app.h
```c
/*
 * Copyright (c) 2026 the OpenSC2-Controller authors
 * SPDX-License-Identifier: MIT
 *
 * app.h: the parts of the blank-canvas firmware. Each hardware part is optional and set up from
 * the board overlay (boards/promicro_nrf52840_nrf52840_uf2.overlay).
 */
#ifndef APP_H_
#define APP_H_

#include <opensc2/opensc2.h>

/* inputs.c: buttons (gpio-keys) and sticks and triggers (ADC). */
int inputs_init(void);
/* CONFIG_APP_ANALOG_SAMPLE: the sticks and triggers, read in the library's `sample` callback. */
void inputs_sample(struct opensc2_state *state);
/* Before powering off: STEAM (without a STEAM key, every key) as the pin that wakes the chip.
 * Returns how many pins were set up. */
int inputs_wake_pins(void);

/* status.c: the status LED (the library's LED status through its pattern player), an RGB(W) LED
 * and an IR LED if they are wired. */
int status_init(void);
void status_mode(enum opensc2_mode mode);
void status_link(enum opensc2_link_state state);
/* The link is Bluetooth's (its own patterns, in blue), set before status_link(). */
void status_bluetooth(bool on);
void status_usb(enum opensc2_usb_state state);
void status_led(const struct opensc2_led *led);
/* A controller setting changed (36 is the IR LED's brightness). */
void status_setting(uint8_t number, int16_t value);
/* Wired, the pairing button held 3 s: the LED stays dark ("release now") while `on`. */
void status_hold_cue(bool on);
/* Everything dark, right before the board powers off. */
void status_off(void);

/* rumble.c: a vibration motor or LRA driver on a PWM channel, if one is wired. */
int rumble_init(void);
void rumble_set(const struct opensc2_rumble *rumble);
void rumble_haptic(const struct opensc2_haptic *haptic);

/* trackpad.c: touch devices of Zephyr's input subsystem as the trackpads, if chosen. */
int trackpad_init(void);

/* imu.c: a sensor of Zephyr's sensor API as the IMU, if aliased as imu0 (imu_fifo.c with
 * CONFIG_APP_IMU_STREAM). A controller setting changed: the IMU's own (48) are handed over. */
int imu_init(void);
void imu_setting(uint8_t number, int16_t value);
/* imu_board.c: the real controller's set-up of an LSM6DSV16X (stream build), before the stream. */
void imu_board_setup(void);


/* battery.c: report 0x43's battery: the level (CONFIG_APP_BATTERY) and a charger's status pin
 * (zephyr,user charger-status-gpios), as far as the board has them. */
int battery_init(void);

/* main.c */
void app_pair_button(bool pressed);
void app_button_pressed(void);

#endif /* APP_H_ */
```

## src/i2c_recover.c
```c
/*
 * Copyright (c) 2026 the OpenSC2-Controller authors
 * SPDX-License-Identifier: MIT
 *
 * i2c_recover.c: free every I2C bus once at boot (CONFIG_APP_I2C_RECOVER, on whenever the board
 * has an I2C bus; untested on hardware), after the I2C drivers start and before the sensor and input drivers talk to their
 * parts, as the real controller does: a reset in the middle of a transfer can leave a part
 * holding SDA low, which blocks the bus until SCL is clocked a few times (Zephyr's
 * i2c_recover_bus()).
 */
#include <zephyr/kernel.h>
#include <zephyr/device.h>
#include <zephyr/devicetree.h>
#include <zephyr/drivers/i2c.h>
#include <zephyr/init.h>
#include <zephyr/logging/log.h>

LOG_MODULE_REGISTER(app_i2c, LOG_LEVEL_INF);

#if defined(CONFIG_APP_I2C_RECOVER)

#define RECOVER(node)                                                                    \
	do {                                                                             \
		const struct device *dev = DEVICE_DT_GET(node);                          \
		int err = device_is_ready(dev) ? i2c_recover_bus(dev) : -ENODEV;         \
                                                                                         \
		if (err && err != -ENOSYS) {                                             \
			LOG_WRN("%s: bus recovery failed (%d)", dev->name, err);         \
		}                                                                        \
	} while (0);

static int recover_buses(void)
{
	DT_FOREACH_STATUS_OKAY(nordic_nrf_twim, RECOVER)
	DT_FOREACH_STATUS_OKAY(nordic_nrf_twi, RECOVER)
	return 0;
}

/* After the I2C drivers (CONFIG_I2C_INIT_PRIORITY), before the sensors and touch modules. */
BUILD_ASSERT(CONFIG_APP_I2C_RECOVER_PRIORITY > CONFIG_I2C_INIT_PRIORITY,
	     "the buses are freed after their drivers start");
SYS_INIT(recover_buses, POST_KERNEL, CONFIG_APP_I2C_RECOVER_PRIORITY);

#endif /* CONFIG_APP_I2C_RECOVER */
```

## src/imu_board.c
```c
/*
 * Copyright (c) 2026 the OpenSC2-Controller authors
 * SPDX-License-Identifier: MIT
 *
 * imu_board.c: the set-up the real controller gives its IMU (an ST LSM6DSV16X) after the driver
 * has started it, following the protocol documentation, for the stream build
 * (CONFIG_APP_IMU_STREAM with an "st,lsm6dsv16x" as imu0; untested on hardware):
 *  - the free-fall time window 63 samples (0 on a board that reports hardware ID 0x45);
 *  - the sensor-fusion block's alpha-blending factor 0.05 (a half float in the embedded-function
 *    registers 0x9E and 0x9F) on boards that report hardware ID 0x48 or lower;
 *  - the accelerometer, then the gyroscope, in high-accuracy mode, where the overlay's rate code
 *    of the high-accuracy table (LSM6DSVXXX_DT_ODR_HA01_AT_250Hz) makes them run at 250 Hz.
 * The hardware ID is the one this board reports (the identity's board revision, 0x48 by
 * default). Each step logs a warning when it fails and the next one still runs, except that the
 * gyroscope is not tried after the accelerometer's mode failed, as on the real controller.
 */
#include <zephyr/kernel.h>
#include <zephyr/devicetree.h>
#include <zephyr/logging/log.h>
#include "app.h"

#if defined(CONFIG_APP_IMU_STREAM) && DT_NODE_HAS_COMPAT(DT_ALIAS(imu0), st_lsm6dsv16x)
#include <zephyr/drivers/sensor.h>
#include <lsm6dsv16x_reg.h>
#include <opensc2/opensc2.h>

LOG_MODULE_REGISTER(imu_board, LOG_LEVEL_INF);

#define FREE_FALL_WINDOW   63
#define ALPHA_BLEND_LO     0x9E
#define ALPHA_BLEND_HI     0x9F
#define HIGH_ACCURACY      1
#define HWID_NO_FREE_FALL  0x45
#define HWID_LAST_BLEND    0x48

static const struct device *const imu = DEVICE_DT_GET(DT_ALIAS(imu0));

/* The driver's configuration starts with the ST register library's context. */
static const stmdev_ctx_t *imu_ctx(void)
{
	return (const stmdev_ctx_t *)imu->config;
}

/* A positive value as an IEEE 754 half float, the format the fusion block takes: scaled into
 * [1, 2) by powers of two (exact in single precision), then ten fraction bits, rounded to the
 * nearest. Enough for the one small constant set here; no zero, subnormal or overflow handling. */
static uint16_t half_float(float value)
{
	int exponent = 0;
	uint32_t fraction;

	while (value >= 2.0f) {
		value *= 0.5f;
		exponent++;
	}
	while (value < 1.0f) {
		value *= 2.0f;
		exponent--;
	}
	fraction = (uint32_t)((value - 1.0f) * 1024.0f + 0.5f);
	if (fraction == 1024u) {
		fraction = 0;
		exponent++;
	}
	return (uint16_t)(((uint32_t)(exponent + 15) << 10) | fraction);
}

void imu_board_setup(void)
{
	struct opensc2_identity id;
	struct sensor_value mode = { .val1 = HIGH_ACCURACY };
	uint16_t half;
	uint8_t lo, hi;
	int32_t ret;

	if (!device_is_ready(imu)) {
		LOG_WRN("IMU not ready: its board set-up is skipped");
		return;
	}
	opensc2_identity_get(&id);

	if (lsm6dsv16x_ff_time_windows_set(imu_ctx(), id.board_revision == HWID_NO_FREE_FALL ?
					   0 : FREE_FALL_WINDOW) != 0) {
		LOG_WRN("IMU: free-fall window not set");
	}

	if (id.board_revision <= HWID_LAST_BLEND) {
		half = half_float(0.05f);   /* 0x2A66 */
		lo = (uint8_t)(half & 0xFFu);
		hi = (uint8_t)(half >> 8);
		ret = lsm6dsv16x_ln_pg_write(imu_ctx(), ALPHA_BLEND_LO, &lo, 1);
		ret += lsm6dsv16x_ln_pg_write(imu_ctx(), ALPHA_BLEND_HI, &hi, 1);
		if (ret != 0) {
			LOG_WRN("IMU: fusion alpha-blending factor not set");
		}
	}

	if (sensor_attr_set(imu, SENSOR_CHAN_ACCEL_XYZ, SENSOR_ATTR_CONFIGURATION, &mode) != 0) {
		LOG_WRN("IMU: accelerometer high-accuracy mode not set");
		return;
	}
	if (sensor_attr_set(imu, SENSOR_CHAN_GYRO_XYZ, SENSOR_ATTR_CONFIGURATION, &mode) != 0) {
		LOG_WRN("IMU: gyroscope high-accuracy mode not set");
	}
}

#else

void imu_board_setup(void)
{
}

#endif
```
